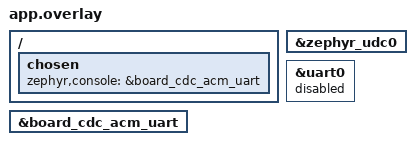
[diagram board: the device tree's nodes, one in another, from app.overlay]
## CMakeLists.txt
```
cmake_minimum_required(VERSION 3.20.0)

find_package(Zephyr REQUIRED HINTS $ENV{ZEPHYR_BASE})
project(adaptive_split_device)

target_sources(app PRIVATE
  src/markers.c
)

if(CONFIG_APP_IDLE_MEASUREMENT)
  target_sources(app PRIVATE src/main_idle.c)
elseif(CONFIG_APP_WEEK4_HEAD)
  set(WEEK4_FIRMWARE_DIR "${CMAKE_CURRENT_SOURCE_DIR}/../ml/results/week4-r3/firmware")
  if(NOT EXISTS "${WEEK4_FIRMWARE_DIR}/head_parameters.h" OR
     NOT EXISTS "${CMAKE_CURRENT_SOURCE_DIR}/generated/week4_graph.h" OR
     NOT EXISTS "${CMAKE_CURRENT_SOURCE_DIR}/generated/week4_inputs.h")
    message(FATAL_ERROR "Week 4 R3 headers are missing; run build_week4_head.ps1")
  endif()
  target_sources(app PRIVATE src/main_week4.c src/week4_head.c src/week4_protocol.c)
  target_include_directories(app PRIVATE src generated "${WEEK4_FIRMWARE_DIR}")
  target_compile_options(app PRIVATE -ffp-contract=off)
elseif(CONFIG_APP_WEEK3_HEAD)
  set(WEEK3_PACKAGE_HEADER "${CMAKE_CURRENT_SOURCE_DIR}/../ml/artifacts/week3/mitdb-week3-fp32-20260925-v2/firmware/head_parameters.h")
  set(WEEK3_INPUT_HEADER "${CMAKE_CURRENT_SOURCE_DIR}/generated/week3_inputs.h")
  if(NOT EXISTS "${WEEK3_PACKAGE_HEADER}" OR NOT EXISTS "${WEEK3_INPUT_HEADER}")
    message(FATAL_ERROR "Week 3 v2 package header or generated input header is missing; run build_week3_head.ps1")
  endif()
  target_sources(app PRIVATE src/main_week3.c src/week3_head.c)
  target_include_directories(app PRIVATE
    "${CMAKE_CURRENT_SOURCE_DIR}/src"
    "${CMAKE_CURRENT_SOURCE_DIR}/generated"
    "${CMAKE_CURRENT_SOURCE_DIR}/../ml/artifacts/week3/mitdb-week3-fp32-20260925-v2/firmware")
  target_compile_options(app PRIVATE -ffp-contract=off)
else()
  target_sources(app PRIVATE src/main.c)
endif()
```

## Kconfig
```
mainmenu "Adaptive Split Inference firmware"

config APP_IDLE_MEASUREMENT
	bool "Build the Week 2 idle-current measurement firmware"
	default n
	help
	  Select the minimal firmware used to measure the PCA10059 idle
	  baseline. The normal Active firmware remains the default.

config APP_WEEK3_HEAD
	bool "Build the Week 3 FP32 head validation firmware"
	default n
	help
	  Run the v2 Conv1/ReLU1/Conv2/ReLU2/MaxPool1d head and expose
	  full FP32 milestone tensors through USB CDC ACM.

config APP_WEEK4_HEAD
	bool "Build the Week 4 R3 all-split FP32 validation firmware"
	default n
	depends on !APP_IDLE_MEASUREMENT && !APP_WEEK3_HEAD
	help
	  Run the authenticated R3 graph from normalized input at each call.
	  Select sample and split 0..10 over USB CDC; benchmark with DWT.

source "Kconfig.zephyr"
```

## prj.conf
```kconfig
CONFIG_GPIO=y

# USB CDC ACM console using the NCS v3.4.0/Zephyr 4.4 next-generation stack.
CONFIG_SERIAL=y
CONFIG_CONSOLE=y
CONFIG_PRINTK=y
CONFIG_UART_CONSOLE=y
CONFIG_STDOUT_CONSOLE=y
CONFIG_UART_LINE_CTRL=y
CONFIG_USB_DEVICE_STACK_NEXT=y
CONFIG_CDC_ACM_SERIAL_INITIALIZE_AT_BOOT=y
CONFIG_CDC_ACM_SERIAL_PID=0x0004
CONFIG_CDC_ACM_SERIAL_PRODUCT_STRING="Adaptive Split Inference SV1"

# The benchmark prints uint64_t fixed-point statistics.
CONFIG_CBPRINTF_FULL_INTEGRAL=y
CONFIG_CORTEX_M_DWT=y
CONFIG_MAIN_STACK_SIZE=4096

# Keep the demo output deterministic and free from unrelated logs.
CONFIG_LOG=n
CONFIG_BOOT_BANNER=n
```

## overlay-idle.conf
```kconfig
# Week 2 PPK2 idle-current baseline. This is a standalone CONF_FILE.
CONFIG_APP_IDLE_MEASUREMENT=y
CONFIG_GPIO=y

# Do not initialize the application USB CDC console or any logging backend.
# This does not modify or replace the factory USB DFU bootloader.
CONFIG_BOARD_SERIAL_BACKEND_CDC_ACM=n
CONFIG_USB_DEVICE_STACK=n
CONFIG_USB_DEVICE_STACK_NEXT=n
CONFIG_CDC_ACM_SERIAL_INITIALIZE_AT_BOOT=n
CONFIG_SERIAL=n
CONFIG_CONSOLE=n
CONFIG_UART_CONSOLE=n
CONFIG_STDOUT_CONSOLE=n
CONFIG_UART_LINE_CTRL=n
CONFIG_PRINTK=n
CONFIG_LOG=n
CONFIG_BOOT_BANNER=n
CONFIG_NCS_BOOT_BANNER=n

CONFIG_MAIN_STACK_SIZE=1024
```

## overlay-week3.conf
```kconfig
# Adds the Week 3 head to the existing Active USB CDC configuration.
CONFIG_APP_WEEK3_HEAD=y
CONFIG_UART_USE_RUNTIME_CONFIGURE=y
CONFIG_INIT_STACKS=y
```

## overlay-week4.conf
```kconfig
# Separate R3 target; retain Week 3 USB CDC fixes and 4096-byte main stack.
CONFIG_APP_WEEK4_HEAD=y
CONFIG_UART_USE_RUNTIME_CONFIGURE=y
CONFIG_INIT_STACKS=y
CONFIG_FPU=y
# Nordic USB DFU application: after MBR, before onboard bootloader at 0xe0000.
# The board's MCUboot slots are inactive (USE_DT_CODE_PARTITION=n).
CONFIG_FLASH_LOAD_SIZE=0xdf000
```

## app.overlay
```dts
/*
 * The PCA10059 board DTS already creates board_cdc_acm_uart. Keep the
 * application choice explicit so the demo can never fall back to UART0.
 */

/ {
	chosen {
		zephyr,console = &board_cdc_acm_uart;
	};
};

&zephyr_udc0 {
	status = "okay";
};

&board_cdc_acm_uart {
	status = "okay";
};

/* The dongle demo has no physical UART console; only USB CDC ACM is used. */
&uart0 {
	status = "disabled";
};
```

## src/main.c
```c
/*
 * Adaptive Split Inference - SV1 Week 1 demo plus Week 2 GPIO markers
 * Target: Nordic nRF52840 Dongle PCA10059 (nrf52840dongle/nrf52840)
 */

#include "markers.h"

#include <stdbool.h>
#include <stdint.h>

#include <cmsis_core.h>
#include <zephyr/device.h>
#include <zephyr/drivers/gpio.h>
#include <zephyr/drivers/uart.h>
#include <zephyr/irq.h>
#include <zephyr/kernel.h>
#include <zephyr/sys/printk.h>

#define LED0_NODE DT_ALIAS(led0)

#define HEARTBEAT_PERIOD_MS       1000
#define HEARTBEAT_TOGGLE_MS       (HEARTBEAT_PERIOD_MS / 2)
#define CONSOLE_POLL_INTERVAL_MS  20
#define STATUS_PERIOD_MS          5000
#define DTR_SETTLE_TIME_MS        100
#define WARMUP_RUN_COUNT          20U
#define MEASUREMENT_RUN_COUNT     20U
#define BENCHMARK_ITERATION_COUNT 10000U

BUILD_ASSERT(DT_NODE_HAS_STATUS(LED0_NODE, okay),
	     "The board must provide an enabled led0 alias");
BUILD_ASSERT(DT_NODE_HAS_COMPAT(DT_CHOSEN(zephyr_console), zephyr_cdc_acm_uart),
	     "The console must be a USB CDC ACM UART");

typedef void (*benchmark_function_t)(uint32_t iteration_count);

static const struct gpio_dt_spec status_led = GPIO_DT_SPEC_GET(LED0_NODE, gpios);
static const struct device *const console_device =
	DEVICE_DT_GET(DT_CHOSEN(zephyr_console));
static volatile uint32_t measured_cycles[MEASUREMENT_RUN_COUNT];
static volatile uint32_t benchmark_sink;
static uint32_t last_min_cycles;
static uint32_t last_max_cycles;
static uint64_t last_average_milli_cycles;
static uint64_t last_deviation_milli_percent;
static bool last_result_passed;
static bool benchmark_result_available;

static inline uint32_t dwt_cycle_count_get(void)
{
	__asm__ volatile("" ::: "memory");
	uint32_t cycle_count = DWT->CYCCNT;
	__asm__ volatile("" ::: "memory");

	return cycle_count;
}

static bool dwt_cycle_counter_init(void)
{
	CoreDebug->DEMCR |= CoreDebug_DEMCR_TRCENA_Msk;
	DWT->CYCCNT = 0U;
	DWT->CTRL |= DWT_CTRL_CYCCNTENA_Msk;
	__DSB();
	__ISB();

	for (uint32_t nop_count = 0U; nop_count < 8U; ++nop_count) {
		__asm__ volatile("nop" ::: "memory");
	}

	return ((DWT->CTRL & DWT_CTRL_NOCYCCNT_Msk) == 0U) &&
	       (DWT->CYCCNT != 0U);
}

static void empty_loop_benchmark(uint32_t iteration_count)
{
	volatile uint32_t iteration;

	for (iteration = 0U; iteration < iteration_count; ++iteration) {
		__asm__ volatile("nop" ::: "memory");
	}

	benchmark_sink = iteration;
}

static uint32_t measure_cycles(benchmark_function_t benchmark_function)
{
	unsigned int irq_key = irq_lock();
	uint32_t start_cycles = dwt_cycle_count_get();

	benchmark_function(BENCHMARK_ITERATION_COUNT);
	uint32_t end_cycles = dwt_cycle_count_get();
	irq_unlock(irq_key);

	return end_cycles - start_cycles;
}

static void print_fixed_point(uint64_t milli_value, const char *suffix)
{
	printk("%llu.%03llu%s", (unsigned long long)(milli_value / 1000U),
	       (unsigned long long)(milli_value % 1000U), suffix);
}

static void run_and_report_benchmark(void)
{
	benchmark_function_t benchmark_function = empty_loop_benchmark;
	uint64_t cycle_sum = 0U;
	uint32_t min_cycles = UINT32_MAX;
	uint32_t max_cycles = 0U;

	printk("DWT benchmark: START\r\n");
	printk("Warm-up runs: %u; measured runs: %u; iterations/run: %u\r\n",
	       WARMUP_RUN_COUNT, MEASUREMENT_RUN_COUNT,
	       BENCHMARK_ITERATION_COUNT);

	for (uint32_t run = 0U; run < WARMUP_RUN_COUNT; ++run) {
		(void)measure_cycles(benchmark_function);
	}

	for (uint32_t run = 0U; run < MEASUREMENT_RUN_COUNT; ++run) {
		uint32_t elapsed_cycles = measure_cycles(benchmark_function);

		measured_cycles[run] = elapsed_cycles;
		cycle_sum += elapsed_cycles;
		if (elapsed_cycles < min_cycles) {
			min_cycles = elapsed_cycles;
		}
		if (elapsed_cycles > max_cycles) {
			max_cycles = elapsed_cycles;
		}
		printk("Run %02u: %u cycles\r\n", run + 1U, elapsed_cycles);
	}

	last_min_cycles = min_cycles;
	last_max_cycles = max_cycles;
	last_average_milli_cycles =
		(cycle_sum * 1000U) / MEASUREMENT_RUN_COUNT;
	last_deviation_milli_percent =
		((uint64_t)(max_cycles - min_cycles) *
		 MEASUREMENT_RUN_COUNT * 100000U) /
		cycle_sum;
	last_result_passed = last_deviation_milli_percent < 1000U;
	benchmark_result_available = true;

	printk("Min: %u cycles\r\n", last_min_cycles);
	printk("Max: %u cycles\r\n", last_max_cycles);
	printk("Average: ");
	print_fixed_point(last_average_milli_cycles, " cycles\r\n");
	printk("Deviation: ");
	print_fixed_point(last_deviation_milli_percent, "%%\r\n");
	printk("RESULT: %s\r\n", last_result_passed ? "PASS" : "FAIL");
}

static void print_banner(bool led_operational, bool dwt_operational,
			 bool markers_operational)
{
	uint32_t cpu_freq_hz = SystemCoreClock;

	printk("\r\n========================================\r\n");
	printk("ADAPTIVE SPLIT INFERENCE - SV1 WEEK 1 + WEEK 2 MARKERS\r\n");
	printk("Board: nRF52840 Dongle PCA10059\r\n");
	printk("CPU: %u MHz\r\n", cpu_freq_hz / 1000000U);
	printk("USB CDC: READY\r\n");
	printk("LED heartbeat: %s\r\n", led_operational ? "RUNNING" : "ERROR");
	printk("GPIO marker self-test: %s\r\n",
	       markers_operational ? "RUNNING" : "ERROR");
	if (markers_operational) {
		printk("GPIO marker self-test: %s ON\r\n",
		       marker_name(markers_self_test_active()));
	} else {
		printk("ERROR: GPIO marker initialization failed\r\n");
	}
	if (!led_operational) {
		printk("ERROR: led0 GPIO initialization or toggle failed\r\n");
	}
	if (!dwt_operational) {
		printk("DWT benchmark: ERROR - CYCCNT unavailable\r\n");
		printk("RESULT: FAIL\r\n");
	}
}

static void print_periodic_status(bool led_operational)
{
	printk("STATUS: USB CDC CONNECTED | LED heartbeat: %s",
	       led_operational ? "RUNNING" : "ERROR");
	if (benchmark_result_available) {
		printk(" | last deviation: ");
		print_fixed_point(last_deviation_milli_percent, "%%");
		printk(" | RESULT: %s", last_result_passed ? "PASS" : "FAIL");
	}
	printk("\r\n");
}

static void update_heartbeat(bool *led_operational, int64_t *next_toggle_ms)
{
	int64_t now_ms = k_uptime_get();

	if (*led_operational && now_ms >= *next_toggle_ms) {
		int result = gpio_pin_toggle_dt(&status_led);

		if (result != 0) {
			*led_operational = false;
		}
		*next_toggle_ms = now_ms + HEARTBEAT_TOGGLE_MS;
	}
}

int main(void)
{
	bool led_operational = gpio_is_ready_dt(&status_led);
	bool markers_operational;
	bool terminal_was_connected = false;
	bool dwt_operational;
	int64_t next_toggle_ms = k_uptime_get() + HEARTBEAT_TOGGLE_MS;
	int64_t next_status_ms = 0;

	if (led_operational) {
		led_operational =
			gpio_pin_configure_dt(&status_led, GPIO_OUTPUT_INACTIVE) == 0;
	}

	dwt_operational = dwt_cycle_counter_init();
	markers_operational = markers_init() == 0;
	if (markers_operational) {
		markers_self_test_start();
	}

	if (!device_is_ready(console_device)) {
		while (true) {
			update_heartbeat(&led_operational, &next_toggle_ms);
			markers_self_test_update(false);
			k_msleep(CONSOLE_POLL_INTERVAL_MS);
		}
	}

	while (true) {
		uint32_t dtr = 0U;
		bool terminal_connected =
			uart_line_ctrl_get(console_device, UART_LINE_CTRL_DTR, &dtr) == 0 &&
			dtr != 0U;

		update_heartbeat(&led_operational, &next_toggle_ms);
		markers_self_test_update(terminal_connected);

		if (terminal_connected && !terminal_was_connected) {
			k_msleep(DTR_SETTLE_TIME_MS);
			update_heartbeat(&led_operational, &next_toggle_ms);
			markers_self_test_update(terminal_connected);
			print_banner(led_operational, dwt_operational,
				     markers_operational);
			if (dwt_operational) {
				run_and_report_benchmark();
			}
			next_status_ms = k_uptime_get() + STATUS_PERIOD_MS;
		} else if (terminal_connected && k_uptime_get() >= next_status_ms) {
			print_periodic_status(led_operational);
			next_status_ms = k_uptime_get() + STATUS_PERIOD_MS;
		}

		terminal_was_connected = terminal_connected;
		k_msleep(CONSOLE_POLL_INTERVAL_MS);
	}

	return 0;
}
```

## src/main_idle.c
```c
/*
 * Week 2 PPK2 idle-current baseline for the PCA10059.
 * D0-D3 stay LOW, every onboard LED stays off, and no workload is run.
 */

#include "markers.h"

#include <stddef.h>

#include <zephyr/devicetree.h>
#include <zephyr/drivers/gpio.h>
#include <zephyr/kernel.h>
#include <zephyr/sys/util.h>

#define LED0_NODE DT_ALIAS(led0)
#define LED1_NODE DT_ALIAS(led1)
#define LED2_NODE DT_ALIAS(led2)
#define LED3_NODE DT_ALIAS(led3)

BUILD_ASSERT(DT_NODE_HAS_STATUS(LED0_NODE, okay),
	     "The board must provide an enabled led0 alias");
BUILD_ASSERT(DT_NODE_HAS_STATUS(LED1_NODE, okay),
	     "The board must provide an enabled led1 alias");
BUILD_ASSERT(DT_NODE_HAS_STATUS(LED2_NODE, okay),
	     "The board must provide an enabled led2 alias");
BUILD_ASSERT(DT_NODE_HAS_STATUS(LED3_NODE, okay),
	     "The board must provide an enabled led3 alias");

static const struct gpio_dt_spec onboard_leds[] = {
	GPIO_DT_SPEC_GET(LED0_NODE, gpios),
	GPIO_DT_SPEC_GET(LED1_NODE, gpios),
	GPIO_DT_SPEC_GET(LED2_NODE, gpios),
	GPIO_DT_SPEC_GET(LED3_NODE, gpios),
};

static void turn_off_onboard_leds(void)
{
	for (size_t index = 0U; index < ARRAY_SIZE(onboard_leds); ++index) {
		if (gpio_is_ready_dt(&onboard_leds[index])) {
			(void)gpio_pin_configure_dt(&onboard_leds[index],
						GPIO_OUTPUT_INACTIVE);
		}
	}
}

int main(void)
{
	/* markers_init() drives Active D0-D3 (P0.13/15/17/20) LOW. */
	(void)markers_init();
	turn_off_onboard_leds();

	/* Block forever so Zephyr's idle thread can place the CPU in idle. */
	k_sleep(K_FOREVER);

	return 0;
}
```

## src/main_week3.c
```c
/* Week 3 v2 FP32 head, USB CDC tensor capture. */

#include "week3_head.h"
#include "week3_inputs.h"
#include "markers.h"

#include <stdbool.h>
#include <stdint.h>
#include <string.h>

#include <zephyr/device.h>
#include <zephyr/drivers/uart.h>
#include <zephyr/kernel.h>
#include <zephyr/sys/printk.h>

BUILD_ASSERT(DT_NODE_HAS_COMPAT(DT_CHOSEN(zephyr_console), zephyr_cdc_acm_uart),
	     "Week 3 requires the USB CDC ACM console");

static const struct device *const console_device = DEVICE_DT_GET(DT_CHOSEN(zephyr_console));
static float activation_a[WEEK3_ACTIVATION_COUNT];
static float activation_b[WEEK3_ACTIVATION_COUNT];

static void dump_tensor(unsigned sample, const char *name, const float *values, unsigned count)
{
	printk("TENSOR %u %s %u\r\n", sample, name, count);
	for (unsigned i = 0; i < count; ++i) {
		uint32_t bits;
		memcpy(&bits, &values[i], sizeof(bits));
		printk("%08x", bits);
		if (i % 16U == 15U || i + 1U == count) {
			printk("\r\n");
			/* Allow the USB CDC TX worker to drain between lines. An unpaced
			 * tensor burst stalled reproducibly in the final P2 rows of RUN 10/11.
			 */
			k_msleep(5);
		} else {
			printk(" ");
		}
	}
	printk("END %s\r\n", name);
}

static void run_sample(unsigned sample, bool trace)
{
	const float *m0 = week3_inputs[sample];
	printk("BEGIN %u %s\r\n", sample, trace ? "TRACE" : "RUN");
	marker_on(MARKER_HEAD);
	week3_conv1(m0, activation_a);
	marker_off(MARKER_HEAD);
	if (trace) {
		dump_tensor(sample, "M1", activation_a, WEEK3_ACTIVATION_COUNT);
	}
	week3_relu(activation_a, WEEK3_ACTIVATION_COUNT);
	if (trace) {
		dump_tensor(sample, "R1", activation_a, WEEK3_ACTIVATION_COUNT);
	}
	marker_on(MARKER_HEAD);
	week3_conv2(activation_a, activation_b);
	marker_off(MARKER_HEAD);
	if (trace) {
		dump_tensor(sample, "M2", activation_b, WEEK3_ACTIVATION_COUNT);
	}
	week3_relu(activation_b, WEEK3_ACTIVATION_COUNT);
	if (trace) {
		dump_tensor(sample, "R2", activation_b, WEEK3_ACTIVATION_COUNT);
	}
	week3_pool(activation_b, activation_a);
	dump_tensor(sample, "P2", activation_a, WEEK3_P2_COUNT);
	size_t unused_stack;
	int stack_result = k_thread_stack_space_get(k_current_get(), &unused_stack);
	if (stack_result == 0) {
		size_t total_stack = k_current_get()->stack_info.size;
		printk("STACK main_peak_bytes=%u main_size_bytes=%u\r\n",
		       (unsigned)(total_stack - unused_stack), (unsigned)total_stack);
	} else {
		printk("STACK ERROR %d\r\n", stack_result);
	}
	printk("DONE %u\r\n", sample);
}

static bool parse_sample(const char *line, const char *prefix, unsigned *sample)
{
	size_t length = strlen(prefix);
	if (strncmp(line, prefix, length) != 0 || line[length] != ' ') {
		return false;
	}
	const char *digits = line + length + 1;
	if (*digits == '\0') {
		return false;
	}
	unsigned value = 0;
	for (; *digits != '\0'; ++digits) {
		if (*digits < '0' || *digits > '9') {
			return false;
		}
		value = value * 10U + (unsigned)(*digits - '0');
		if (value >= WEEK3_SAMPLE_COUNT) {
			return false;
		}
	}
	*sample = value;
	return true;
}

static void process_line(const char *line)
{
	unsigned sample;
	if (parse_sample(line, "TRACE", &sample)) {
		run_sample(sample, true);
	} else if (parse_sample(line, "RUN", &sample)) {
		run_sample(sample, false);
	} else {
		printk("ERROR expected TRACE n or RUN n, 0 <= n < 20\r\n");
	}
}

int main(void)
{
	char line[32];
	unsigned length = 0;
	bool connected_before = false;
	if (!device_is_ready(console_device) || markers_init() != 0) {
		return -1;
	}
	/* CDC ACM poll_out discards bytes when its TX ring fills without flow
	 * control. This enables the driver's internal blocking backpressure.
	 */
	struct uart_config uart_cfg = {
		.baudrate = 115200,
		.parity = UART_CFG_PARITY_NONE,
		.stop_bits = UART_CFG_STOP_BITS_1,
		.data_bits = UART_CFG_DATA_BITS_8,
		.flow_ctrl = UART_CFG_FLOW_CTRL_RTS_CTS,
	};
	if (uart_configure(console_device, &uart_cfg) != 0) {
		return -1;
	}
	/* The NCS CDC ACM driver arms its first USB OUT transfer on RX enable.
	 * poll_in() only drains the RX ring and cannot arm that first transfer.
	 */
	uart_irq_rx_enable(console_device);
	while (true) {
		uint32_t dtr = 0;
		bool connected = uart_line_ctrl_get(console_device, UART_LINE_CTRL_DTR, &dtr) == 0 && dtr != 0;
		if (connected && !connected_before) {
			k_msleep(100);
			printk("READY WEEK3 mitdb-week3-fp32-20260925-v2 P2 1x16x180\r\n");
			printk("COMMAND TRACE n or RUN n (0..19)\r\n");
			length = 0;
		}
		if (connected) {
			unsigned char byte;
			while (uart_poll_in(console_device, &byte) == 0) {
				if (byte == '\n') {
					line[length] = '\0';
					process_line(line);
					length = 0;
				} else if (byte != '\r') {
					if (length + 1U < sizeof(line)) {
						line[length++] = (char)byte;
					} else {
						length = 0;
						printk("ERROR command too long\r\n");
					}
				}
			}
		} else {
			length = 0;
		}
		connected_before = connected;
		k_msleep(10);
	}
	return 0;
}
```

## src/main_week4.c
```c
/* Week 4 R3: one runtime-selected head, separate from Week 3 entry point. */
#include "week4_head.h"
#include "week4_inputs.h"
#include "week4_protocol.h"
#include "markers.h"

#include <stdbool.h>
#include <stdint.h>
#include <string.h>

#include <cmsis_core.h>
#include <zephyr/device.h>
#include <zephyr/drivers/uart.h>
#include <zephyr/irq.h>
#include <zephyr/kernel.h>
#include <zephyr/sys/printk.h>

#define WARMUP_COUNT 20U
#define MEASURE_COUNT 100U

BUILD_ASSERT(DT_NODE_HAS_COMPAT(DT_CHOSEN(zephyr_console), zephyr_cdc_acm_uart),
	     "Week 4 requires USB CDC ACM");
static const struct device *const console_device = DEVICE_DT_GET(DT_CHOSEN(zephyr_console));
static uint32_t measured_cycles[MEASURE_COUNT];
static bool dwt_ready;

static inline uint32_t cycle_count(void)
{
	__asm__ volatile("" ::: "memory");
	uint32_t cycles = DWT->CYCCNT;
	__asm__ volatile("" ::: "memory");
	return cycles;
}

static bool init_dwt(void)
{
	CoreDebug->DEMCR |= CoreDebug_DEMCR_TRCENA_Msk;
	DWT->CYCCNT = 0;
	DWT->CTRL |= DWT_CTRL_CYCCNTENA_Msk;
	__DSB();
	__ISB();
	for (unsigned i = 0; i < 8; ++i) {
		__asm__ volatile("nop" ::: "memory");
	}
	return (DWT->CTRL & DWT_CTRL_NOCYCCNT_Msk) == 0 && DWT->CYCCNT != 0;
}

static void dump_tensor(unsigned sample, unsigned split, const struct week4_result *result)
{
	const struct week4_shape *shape = &result->shape;
	printk("TENSOR %u %s %u FP32 %s %u", sample, week4_sample_ids[sample], split,
	       shape->rank == 3U ? "NCL" : "NC", shape->rank);
	for (unsigned i = 0; i < shape->rank; ++i) {
		printk(" %u", shape->dims[i]);
	}
	printk(" %u\r\n", shape->count);
	for (unsigned i = 0; i < shape->count; ++i) {
		uint32_t bits;
		memcpy(&bits, &result->values[i], sizeof(bits));
		printk("%08x", bits);
		if (i % 16U == 15U || i + 1U == shape->count) {
			printk("\r\n");
			/* Retain Week 3's verified USB worker pacing. */
			k_msleep(5);
		} else {
			printk(" ");
		}
	}
	printk("END %u %u\r\n", sample, split);
}

static int measure_head(unsigned sample, unsigned split, struct week4_result *result,
			uint32_t *elapsed)
{
	/* GPIO writes and USB output are outside the cycle interval. Disable IRQs
	 * only for one head run to isolate compute; re-enable between iterations.
	 * No baseline subtraction: s=0 measures the identity/API bookkeeping.
	 * uint32 subtraction handles one wrap (67.1 s at 64 MHz).
	 */
	marker_on(MARKER_HEAD);
	unsigned key = irq_lock();
	uint32_t start = cycle_count();
	int status = week4_run_head(split, week4_inputs[sample], result);
	uint32_t end = cycle_count();
	irq_unlock(key);
	marker_off(MARKER_HEAD);
	*elapsed = end - start;
	return status;
}

static void process_command(const struct week4_command *command)
{
	unsigned sample = command->sample;
	unsigned split = command->split;
	bool bench = command->type == WEEK4_BENCH;
	struct week4_result result;
	if (bench && !dwt_ready) {
		printk("ERROR DWT unavailable\r\n");
		return;
	}
	printk("BEGIN %u %s %u %s\r\n", sample, week4_sample_ids[sample], split,
	       bench ? "BENCH" : "RUN");
	if (bench) {
		uint32_t unused;
		for (unsigned i = 0; i < WARMUP_COUNT; ++i) {
			if (measure_head(sample, split, &result, &unused) != 0) {
				printk("ERROR head warmup\r\n");
				return;
			}
		}
		for (unsigned i = 0; i < MEASURE_COUNT; ++i) {
			if (measure_head(sample, split, &result, &measured_cycles[i]) != 0) {
				printk("ERROR head measurement\r\n");
				return;
			}
		}
		/* All USB/logging starts after the entire measurement batch. */
		printk("TIMING %u %s %u warmup=%u measured=%u cpu_hz=%u irq=locked baseline=raw\r\n",
		       sample, week4_sample_ids[sample], split, WARMUP_COUNT, MEASURE_COUNT,
		       SystemCoreClock);
		for (unsigned i = 0; i < MEASURE_COUNT; ++i) {
			printk("CYCLES %u %u %u %u\r\n", sample, split, i, measured_cycles[i]);
			if (i % 16U == 15U) {
				k_msleep(5);
			}
		}
	} else {
		marker_on(MARKER_HEAD);
		int status = week4_run_head(split, week4_inputs[sample], &result);
		marker_off(MARKER_HEAD);
		if (status != 0) {
			printk("ERROR head\r\n");
			return;
		}
	}
	dump_tensor(sample, split, &result);
	size_t unused_stack;
	if (k_thread_stack_space_get(k_current_get(), &unused_stack) == 0) {
		size_t size = k_current_get()->stack_info.size;
		printk("STACK main_peak_bytes=%u main_size_bytes=%u\r\n",
		       (unsigned)(size - unused_stack), (unsigned)size);
	}
	printk("DONE %u %u %s\r\n", sample, split, bench ? "BENCH" : "RUN");
}

int main(void)
{
	char line[48];
	unsigned length = 0;
	bool discard = false;
	bool connected_before = false;
	if (!device_is_ready(console_device) || markers_init() != 0) {
		return -1;
	}
	/* Both fixes from Week 3: TX backpressure and initial USB OUT arming. */
	struct uart_config uart_cfg = {
		.baudrate = 115200,
		.parity = UART_CFG_PARITY_NONE,
		.stop_bits = UART_CFG_STOP_BITS_1,
		.data_bits = UART_CFG_DATA_BITS_8,
		.flow_ctrl = UART_CFG_FLOW_CTRL_RTS_CTS,
	};
	if (uart_configure(console_device, &uart_cfg) != 0) {
		return -1;
	}
	uart_irq_rx_enable(console_device);
	dwt_ready = init_dwt();
	while (true) {
		uint32_t dtr = 0;
		bool connected = uart_line_ctrl_get(console_device, UART_LINE_CTRL_DTR, &dtr) == 0 && dtr != 0;
		if (connected && !connected_before) {
			k_msleep(100);
			printk("READY WEEK4 R3 %s samples=20 splits=11 DWT=%s\r\n",
			       WEEK4_MANIFEST_SHA256, dwt_ready ? "READY" : "ERROR");
			printk("COMMAND RUN n s or BENCH n s (n=0..19 s=0..10)\r\n");
			length = 0;
			discard = false;
		}
		if (connected) {
			unsigned char byte;
			while (uart_poll_in(console_device, &byte) == 0) {
				if (byte == '\n') {
					line[length] = '\0';
					struct week4_command command;
					if (!discard && week4_parse_command(line, &command) == 0) {
						process_command(&command);
					} else {
						printk("ERROR expected RUN n s or BENCH n s (n=0..19 s=0..10)\r\n");
					}
					length = 0;
					discard = false;
				} else if (byte != '\r' && !discard) {
					if (byte == '\0' || length + 1U >= sizeof(line)) {
						discard = true; /* Reject the entire line, including its suffix. */
					} else {
						line[length++] = (char)byte;
					}
				}
			}
		} else {
			length = 0;
			discard = false;
		}
		connected_before = connected;
		k_msleep(10);
	}
	return 0;
}
```

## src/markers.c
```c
/*
 * GPIO timing markers for Week 2.
 *
 * All marker signals are on GPIO Port 0. Direct OUTSET/OUTCLR writes make a
 * marker edge a single peripheral-register write, as required for timing
 * measurements. A static kernel timer keeps the self-test cadence independent
 * of console traffic; printing remains in main-thread context.
 */

#include "markers.h"

#include <errno.h>
#include <stdint.h>

#include <hal/nrf_gpio.h>
#include <zephyr/device.h>
#include <zephyr/devicetree.h>
#include <zephyr/drivers/gpio.h>
#include <zephyr/kernel.h>
#include <zephyr/sys/atomic.h>
#include <zephyr/sys/printk.h>
#include <zephyr/sys/util.h>

#define GPIO0_NODE              DT_NODELABEL(gpio0)
#define MARKER_HIGH_TIME_MS     500
#define MARKER_HEAD_PIN         13U
#define MARKER_PROTECTION_PIN   15U
#define MARKER_TX_PIN           17U
#define MARKER_WAIT_PIN         20U
#define MARKER_ALL_MASK         (BIT(MARKER_HEAD_PIN) | \
				 BIT(MARKER_PROTECTION_PIN) | \
				 BIT(MARKER_TX_PIN) | \
				 BIT(MARKER_WAIT_PIN))

BUILD_ASSERT(DT_NODE_HAS_STATUS(GPIO0_NODE, okay),
	     "GPIO Port 0 must be enabled for timing markers");

struct marker_description {
	gpio_pin_t pin;
	uint32_t mask;
	const char *name;
};

static const struct device *const marker_port = DEVICE_DT_GET(GPIO0_NODE);
static const struct marker_description marker_descriptions[MARKER_COUNT] = {
	[MARKER_HEAD] = {
		.pin = MARKER_HEAD_PIN,
		.mask = BIT(MARKER_HEAD_PIN),
		.name = "HEAD",
	},
	[MARKER_PROTECTION] = {
		.pin = MARKER_PROTECTION_PIN,
		.mask = BIT(MARKER_PROTECTION_PIN),
		.name = "PROTECTION",
	},
	[MARKER_TX] = {
		.pin = MARKER_TX_PIN,
		.mask = BIT(MARKER_TX_PIN),
		.name = "TX",
	},
	[MARKER_WAIT] = {
		.pin = MARKER_WAIT_PIN,
		.mask = BIT(MARKER_WAIT_PIN),
		.name = "WAIT",
	},
};

static atomic_t active_marker = ATOMIC_INIT(MARKER_HEAD);
static atomic_t transition_count;
static atomic_val_t last_observed_transition;
static bool markers_initialized;
static bool self_test_running;

static bool marker_is_valid(enum marker_id marker)
{
	return (unsigned int)marker < MARKER_COUNT;
}

static void markers_all_low(void)
{
	NRF_P0->OUTCLR = MARKER_ALL_MASK;
}

static void marker_self_test_expiry(struct k_timer *timer)
{
	enum marker_id current = (enum marker_id)atomic_get(&active_marker);
	enum marker_id next = (enum marker_id)((current + 1) % MARKER_COUNT);

	ARG_UNUSED(timer);
	marker_off(current);
	atomic_set(&active_marker, next);
	marker_on(next);
	atomic_inc(&transition_count);
}

K_TIMER_DEFINE(marker_self_test_timer, marker_self_test_expiry, NULL);

int markers_init(void)
{
	k_timer_stop(&marker_self_test_timer);
	self_test_running = false;
	markers_initialized = false;
	markers_all_low();

	if (!device_is_ready(marker_port)) {
		return -ENODEV;
	}

	for (enum marker_id marker = MARKER_HEAD;
	     marker < MARKER_COUNT;
	     marker = (enum marker_id)(marker + 1)) {
		int result = gpio_pin_configure(marker_port,
					marker_descriptions[marker].pin,
					GPIO_OUTPUT_INACTIVE);

		if (result != 0) {
			return result;
		}
	}

	markers_initialized = true;

	return 0;
}

void marker_on(enum marker_id marker)
{
	if (marker_is_valid(marker)) {
		NRF_P0->OUTSET = marker_descriptions[marker].mask;
	}
}

void marker_off(enum marker_id marker)
{
	if (marker_is_valid(marker)) {
		NRF_P0->OUTCLR = marker_descriptions[marker].mask;
	}
}

void markers_self_test_start(void)
{
	if (!markers_initialized) {
		return;
	}

	atomic_set(&active_marker, MARKER_HEAD);
	atomic_set(&transition_count, 0);
	last_observed_transition = 0;
	markers_all_low();
	marker_on(MARKER_HEAD);
	self_test_running = true;
	k_timer_start(&marker_self_test_timer, K_MSEC(MARKER_HIGH_TIME_MS),
		      K_MSEC(MARKER_HIGH_TIME_MS));
}

void markers_self_test_update(bool log_enabled)
{
	atomic_val_t observed_transition;
	enum marker_id marker;

	if (!self_test_running) {
		return;
	}

	observed_transition = atomic_get(&transition_count);
	if (observed_transition == last_observed_transition) {
		return;
	}

	last_observed_transition = observed_transition;
	if (log_enabled) {
		marker = (enum marker_id)atomic_get(&active_marker);
		printk("GPIO marker self-test: %s ON (P0.%u)\r\n",
		       marker_descriptions[marker].name,
		       (unsigned int)marker_descriptions[marker].pin);
	}
}

const char *marker_name(enum marker_id marker)
{
	return marker_is_valid(marker) ? marker_descriptions[marker].name : "INVALID";
}

enum marker_id markers_self_test_active(void)
{
	return (enum marker_id)atomic_get(&active_marker);
}
```

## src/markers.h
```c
/*
 * GPIO timing markers for the PCA10059 measurement header.
 */

#ifndef ADAPTIVE_SPLIT_MARKERS_H_
#define ADAPTIVE_SPLIT_MARKERS_H_

#include <stdbool.h>

enum marker_id {
	MARKER_HEAD = 0,
	MARKER_PROTECTION,
	MARKER_TX,
	MARKER_WAIT,
	MARKER_COUNT
};

/* Configure every marker as an output driven LOW. */
int markers_init(void);

/* Each call performs exactly one write to the GPIO Port 0 set/clear register. */
void marker_on(enum marker_id marker);
void marker_off(enum marker_id marker);

/* Run the non-blocking 500 ms-per-marker hardware self-test. */
void markers_self_test_start(void);
void markers_self_test_update(bool log_enabled);

const char *marker_name(enum marker_id marker);
enum marker_id markers_self_test_active(void);

#endif /* ADAPTIVE_SPLIT_MARKERS_H_ */
```

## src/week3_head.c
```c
#include "week3_head.h"
#include "head_parameters.h"

void week3_conv1(const float *m0, float *m1)
{
	for (unsigned oc = 0; oc < WEEK3_CHANNELS; ++oc) {
		for (unsigned x = 0; x < WEEK3_INPUT_LENGTH; ++x) {
			float sum = 0.0f;
			for (unsigned k = 0; k < 5; ++k) {
				int source = (int)x + (int)k - 2;
				if (source >= 0 && source < WEEK3_INPUT_LENGTH) {
					sum += m0[source] * sv3_conv1_weight[oc * 5 + k];
				}
			}
			m1[oc * WEEK3_INPUT_LENGTH + x] = sum + sv3_conv1_bias[oc];
		}
	}
}

void week3_relu(float *tensor, unsigned count)
{
	for (unsigned i = 0; i < count; ++i) {
		if (tensor[i] < 0.0f) {
			tensor[i] = 0.0f;
		}
	}
}

void week3_conv2(const float *r1, float *m2)
{
	for (unsigned oc = 0; oc < WEEK3_CHANNELS; ++oc) {
		for (unsigned x = 0; x < WEEK3_INPUT_LENGTH; ++x) {
			float sum = 0.0f;
			for (unsigned ic = 0; ic < WEEK3_CHANNELS; ++ic) {
				for (unsigned k = 0; k < 5; ++k) {
					int source = (int)x + (int)k - 2;
					if (source >= 0 && source < WEEK3_INPUT_LENGTH) {
						unsigned weight = (oc * WEEK3_CHANNELS + ic) * 5 + k;
						sum += r1[ic * WEEK3_INPUT_LENGTH + (unsigned)source] *
						       sv3_conv2_weight[weight];
					}
				}
			}
			m2[oc * WEEK3_INPUT_LENGTH + x] = sum + sv3_conv2_bias[oc];
		}
	}
}

void week3_pool(const float *r2, float *p2)
{
	for (unsigned channel = 0; channel < WEEK3_CHANNELS; ++channel) {
		for (unsigned x = 0; x < WEEK3_OUTPUT_LENGTH; ++x) {
			float left = r2[channel * WEEK3_INPUT_LENGTH + 2 * x];
			float right = r2[channel * WEEK3_INPUT_LENGTH + 2 * x + 1];
			p2[channel * WEEK3_OUTPUT_LENGTH + x] = left > right ? left : right;
		}
	}
}
```

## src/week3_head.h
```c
#ifndef WEEK3_HEAD_H
#define WEEK3_HEAD_H

#define WEEK3_INPUT_LENGTH 360
#define WEEK3_CHANNELS 16
#define WEEK3_OUTPUT_LENGTH 180
#define WEEK3_ACTIVATION_COUNT (WEEK3_CHANNELS * WEEK3_INPUT_LENGTH)
#define WEEK3_P2_COUNT (WEEK3_CHANNELS * WEEK3_OUTPUT_LENGTH)

/* M0 is already normalized by SV3. No preprocessing is performed here. */
void week3_conv1(const float *m0, float *m1);
void week3_relu(float *tensor, unsigned count);
void week3_conv2(const float *r1, float *m2);
void week3_pool(const float *r2, float *p2);

#endif
```

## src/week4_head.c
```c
#include "week4_head.h"
#include "head_parameters.h"

#include <stddef.h>

enum op_type { OP_CONV, OP_RELU, OP_POOL, OP_IDENTITY, OP_LINEAR };

struct head_op {
	enum op_type type;
	unsigned in_channels;
	unsigned out_channels;
	unsigned length;
	const float *weight;
	const float *bias;
};

/* Generated only from the authenticated R3 graph and split manifest. */
#include "week4_graph.h"

static float activation_a[WEEK4_BUFFER_COUNT];
static float activation_b[WEEK4_BUFFER_COUNT];

/* Generalization of Week 3's validated oc/x/ic/k accumulation order and
 * bias-after-sum FP32 kernels. Zero padding, OIK weights, NCL activation.
 */
static void conv(const struct head_op *op, const float *input, float *output)
{
	for (unsigned oc = 0; oc < op->out_channels; ++oc) {
		for (unsigned x = 0; x < op->length; ++x) {
			float sum = 0.0f;
			for (unsigned ic = 0; ic < op->in_channels; ++ic) {
				for (unsigned k = 0; k < 5; ++k) {
					int source = (int)x + (int)k - 2;
					if (source >= 0 && source < (int)op->length) {
						unsigned weight = (oc * op->in_channels + ic) * 5 + k;
						sum += input[ic * op->length + (unsigned)source] * op->weight[weight];
					}
				}
			}
			output[oc * op->length + x] = sum + op->bias[oc];
		}
	}
}

static void relu(float *values, unsigned count)
{
	for (unsigned i = 0; i < count; ++i) {
		if (values[i] < 0.0f) {
			values[i] = 0.0f;
		}
	}
}

static void pool(const struct head_op *op, const float *input, float *output)
{
	unsigned length = op->length / 2U;
	for (unsigned channel = 0; channel < op->in_channels; ++channel) {
		for (unsigned x = 0; x < length; ++x) {
			float left = input[channel * op->length + 2U * x];
			float right = input[channel * op->length + 2U * x + 1U];
			output[channel * length + x] = left > right ? left : right;
		}
	}
}

static void linear(const struct head_op *op, const float *input, float *output)
{
	for (unsigned oc = 0; oc < op->out_channels; ++oc) {
		float sum = 0.0f;
		for (unsigned ic = 0; ic < op->in_channels; ++ic) {
			sum += input[ic] * op->weight[oc * op->in_channels + ic];
		}
		output[oc] = sum + op->bias[oc];
	}
}

int week4_get_shape(unsigned split, struct week4_shape *shape)
{
	if (shape == NULL || split >= WEEK4_SPLIT_COUNT) {
		return -1;
	}
	*shape = split_shapes[split];
	return 0;
}

int week4_run_head(unsigned split, const float *input, struct week4_result *result)
{
	if (result == NULL) {
		return -1;
	}
	*result = (struct week4_result){0};
	if (input == NULL || week4_get_shape(split, &result->shape) != 0) {
		return -1;
	}
	const float *current = input;
	for (unsigned i = 0; i < split_op_counts[split]; ++i) {
		const struct head_op *op = &head_ops[i];
		float *next = current == activation_a ? activation_b : activation_a;
		switch (op->type) {
		case OP_CONV:
			conv(op, current, next);
			current = next;
			break;
		case OP_RELU:
			relu((float *)current, op->out_channels * op->length);
			break;
		case OP_POOL:
			pool(op, current, next);
			current = next;
			break;
		case OP_LINEAR:
			linear(op, current, next);
			current = next;
			break;
		case OP_IDENTITY:
			/* Flatten preserves C order; eval Dropout has no scaling. */
			break;
		}
	}
	result->values = current;
	return 0;
}
```

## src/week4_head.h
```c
#ifndef WEEK4_HEAD_H
#define WEEK4_HEAD_H

#include <stdint.h>

#define WEEK4_SPLIT_COUNT 11U
#define WEEK4_INPUT_COUNT 360U
#define WEEK4_BUFFER_COUNT 5760U

struct week4_shape {
	unsigned rank;
	unsigned dims[3];
	unsigned count;
};

struct week4_result {
	const float *values;
	struct week4_shape shape;
};

/* Single-threaded, no heap. A returned activation lives until the next call.
 * s=0 aliases the original input. Input must not alias the private workspace.
 * Each call restarts at input, never at the preceding split's activation.
 * Returns -1 for invalid arguments, clearing result when it is supplied.
 */
int week4_run_head(unsigned split, const float *input, struct week4_result *result);
int week4_get_shape(unsigned split, struct week4_shape *shape);

#endif
```

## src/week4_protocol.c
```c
#include "week4_protocol.h"
#include "week4_head.h"
#include "week4_inputs.h"

#include <stddef.h>
#include <string.h>

static int parse_number(const char **cursor, unsigned limit, unsigned *number)
{
	const char *p = *cursor;
	unsigned value = 0;
	if (*p < '0' || *p > '9') {
		return -1;
	}
	do {
		value = value * 10U + (unsigned)(*p++ - '0');
		if (value >= limit) {
			return -1;
		}
	} while (*p >= '0' && *p <= '9');
	*cursor = p;
	*number = value;
	return 0;
}

int week4_parse_command(const char *line, struct week4_command *command)
{
	if (line == NULL || command == NULL) {
		return -1;
	}
	struct week4_command parsed = {0};
	const char *p;
	if (strncmp(line, "RUN ", 4) == 0) {
		parsed.type = WEEK4_RUN;
		p = line + 4;
	} else if (strncmp(line, "BENCH ", 6) == 0) {
		parsed.type = WEEK4_BENCH;
		p = line + 6;
	} else {
		return -1;
	}
	if (parse_number(&p, WEEK4_SAMPLE_COUNT, &parsed.sample) != 0 || *p++ != ' ' ||
	    parse_number(&p, WEEK4_SPLIT_COUNT, &parsed.split) != 0 || *p != '\0') {
		return -1;
	}
	*command = parsed;
	return 0;
}
```

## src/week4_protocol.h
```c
#ifndef WEEK4_PROTOCOL_H
#define WEEK4_PROTOCOL_H

enum week4_command_type { WEEK4_RUN, WEEK4_BENCH };
struct week4_command {
	enum week4_command_type type;
	unsigned sample;
	unsigned split;
};
int week4_parse_command(const char *line, struct week4_command *command);

#endif
```
